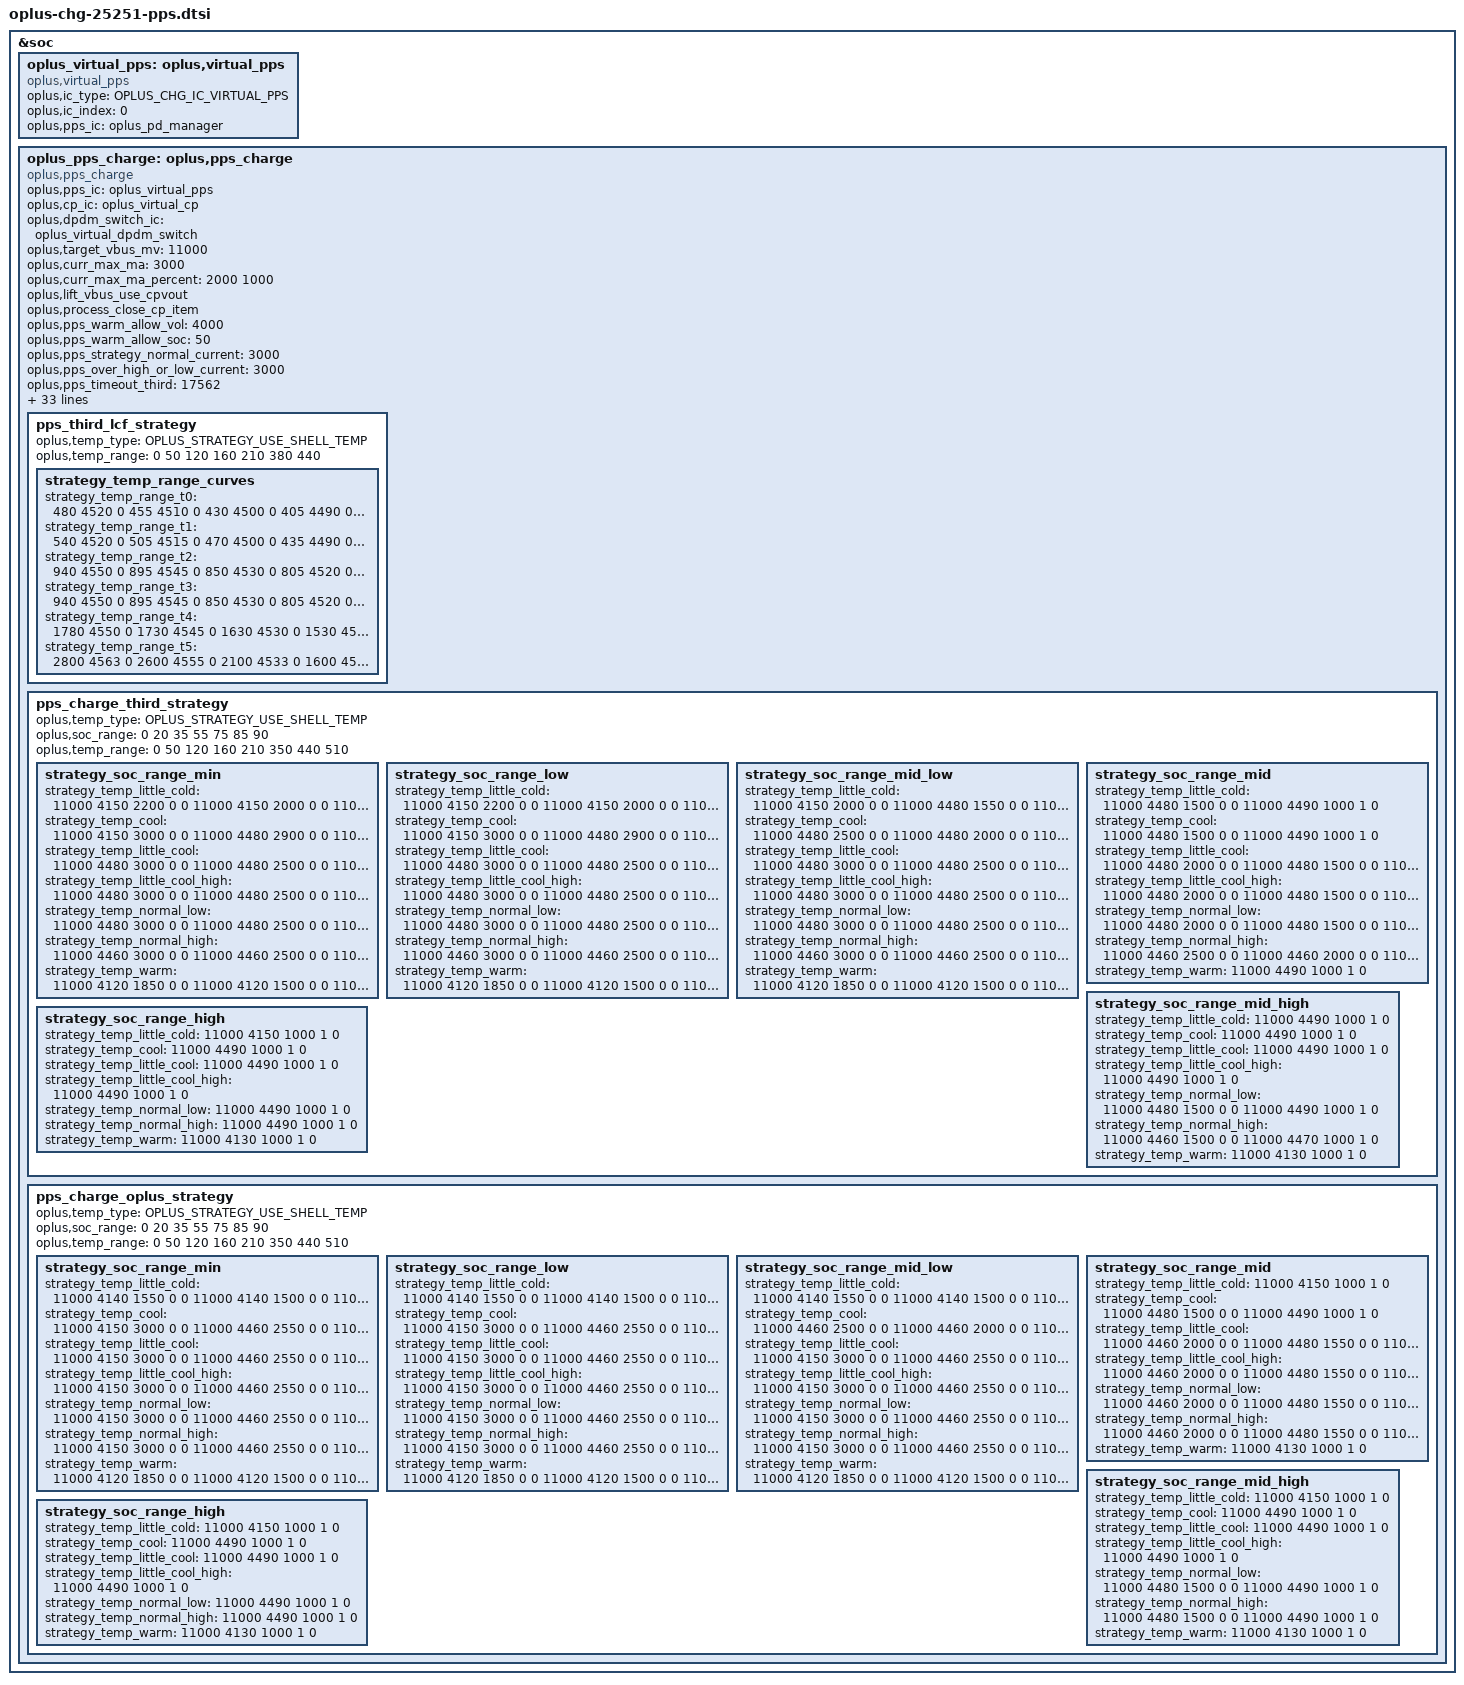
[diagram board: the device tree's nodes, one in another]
&soc {
	oplus_virtual_pps: oplus,virtual_pps {
		compatible = "oplus,virtual_pps";
		oplus,ic_type = <OPLUS_CHG_IC_VIRTUAL_PPS>;
		oplus,ic_index = <0>;
		oplus,pps_ic = <&oplus_pd_manager>;
	};
	oplus_pps_charge: oplus,pps_charge {
		compatible = "oplus,pps_charge";
		oplus,pps_ic = <&oplus_virtual_pps>;
		oplus,cp_ic = <&oplus_virtual_cp>;
		oplus,dpdm_switch_ic = <&oplus_virtual_dpdm_switch>;

		oplus,target_vbus_mv = <11000>;
		oplus,curr_max_ma = <3000>;
		oplus,curr_max_ma_percent = <2000 /* 75% ibus */
					     1000 /* 85% ibus */>;
		oplus,lift_vbus_use_cpvout;
		oplus,process_close_cp_item;

		oplus,pps_warm_allow_vol = <4000>;
		oplus,pps_warm_allow_soc = <50>;
		oplus,pps_strategy_normal_current = <3000>;
		oplus,pps_over_high_or_low_current = <3000>;
		oplus,pps_timeout_third = <17562>;
		oplus,pps_timeout_oplus = <17562>;
		oplus,pps_ibat_over_third = <7400>;
		oplus,pps_ibat_over_oplus = <7400>;
		oplus,pps_full_cool_sw_vbat = <4490>;
		oplus,pps_full_normal_sw_vbat = <4500>;
		oplus,pps_full_normal_hw_vbat = <4490>;
		oplus,pps_full_ffc_vbat = <4545>;
		oplus,pps_full_warm_vbat = <4130>;
		oplus,pps_full_cool_sw_vbat_third = <4490>;
		oplus,pps_full_normal_sw_vbat_third= <4490>;
		oplus,pps_full_normal_hw_vbat_third = <4500>;
		oplus,pps_current_change_timeout = <100>;
		oplus,pps_r_default = <270 45 10 45 20 20 20>;
		oplus,pps_rmos_mohm = <5>;
		oplus,pps_r_limit = <150 100 80 70 30>;
		oplus,pps_strategy_batt_high_temp = <395 420 440 390 415 435>;
		oplus,pps_strategy_high_current = <3000 2000 1300 3000 3000 2000>;
		oplus,pps_little_cool_high_temp = <210>;
		oplus,curve_strategy_name = "pps_ufcs_curve_v2";
		oplus,pps_charge_strategy_soc = <0 20 35 55 75 85 85>;
		oplus,pps_charge_strategy_temp = <0 50 120 160 350 440 510>;
		oplus,pps_low_curr_full_strategy_temp = <0 200 350 440>;

		oplus,plc_strategy-data = <&cp_2t1_simple_strategy>;
		oplus,plc_strategy-names = "default";

		oplus,temperature_strategy_name = "cgcl";
		oplus,temperature_strategy_data = <OPLUS_STRATEGY_USE_SHELL_TEMP
						    0   420 3000 1 0
						    415 440 2000 2 0
						    435 450 1300 2 1>;

		pps_third_lcf_strategy {
			oplus,temp_type = <OPLUS_STRATEGY_USE_SHELL_TEMP>;
			oplus,temp_range = <0 50 120 160 210 380 440>;

			strategy_temp_range_curves {
				strategy_temp_range_t0 =	<480 4520 0
								 455 4510 0
								 430 4500 0
								 405 4490 0
								 380 4480 1>;
				strategy_temp_range_t1 =	<540 4520 0
								 505 4515 0
								 470 4500 0
								 435 4490 0
								 400 4480 1>;
				strategy_temp_range_t2 =	<940 4550 0
								 895 4545 0
								 850 4530 0
								 805 4520 0
								 760 4510 1>;
				strategy_temp_range_t3 =	<940 4550 0
								 895 4545 0
								 850 4530 0
								 805 4520 0
								 760 4510 1>;
				strategy_temp_range_t4 =	<1780 4550 0
								 1730 4545 0
								 1630 4530 0
								 1530  4520 0
								 1380  4510 1>;
				strategy_temp_range_t5 =	<2800 4563 0
								 2600 4555 0
								 2100 4533 0
								 1600 4513 0
								 1000 4467 1>;
			};
		};

		pps_charge_third_strategy {
			oplus,temp_type = <OPLUS_STRATEGY_USE_SHELL_TEMP>;
			oplus,soc_range = <0 20 35 55 75 85 90>;
			oplus,temp_range = <0 50 120 160 210 350 440 510>;

			strategy_soc_range_min {
				strategy_temp_little_cold =	<11000 4150 2200 0 0
								11000 4150 2000 0 0
								11000 4480 1550 0 0
								11000 4480 1500 0 0
								11000 4490 1000 1 0>;
				strategy_temp_cool =		<11000 4150 3000 0 0
								11000 4480 2900 0 0
								11000 4480 2500 0 0
								11000 4480 2000 0 0
								11000 4480 1550 0 0
								11000 4480 1500 0 0
								11000 4490 1000 1 0>;
				strategy_temp_little_cool =	<11000 4480 3000 0 0
								11000 4480 2500 0 0
								11000 4480 2000 0 0
								11000 4480 1500 0 0
								11000 4490 1000 1 0>;
				strategy_temp_little_cool_high = <11000 4480 3000 0 0
								11000 4480 2500 0 0
								11000 4480 2000 0 0
								11000 4480 1500 0 0
								11000 4490 1000 1 0>;
				strategy_temp_normal_low =	<11000 4480 3000 0 0
								11000 4480 2500 0 0
								11000 4480 2000 0 0
								11000 4480 1500 0 0
								11000 4490 1000 1 0>;
				strategy_temp_normal_high =	<11000 4460 3000 0 0
								11000 4460 2500 0 0
								11000 4460 2000 0 0
								11000 4460 1500 0 0
								11000 4470 1000 1 0>;
				strategy_temp_warm =		<11000 4120 1850 0 0
								11000 4120 1500 0 0
								11000 4130 1000 1 0>;
			};
			strategy_soc_range_low {
				strategy_temp_little_cold =	<11000 4150 2200 0 0
								11000 4150 2000 0 0
								11000 4480 1550 0 0
								11000 4480 1500 0 0
								11000 4490 1000 1 0>;
				strategy_temp_cool =		<11000 4150 3000 0 0
								11000 4480 2900 0 0
								11000 4480 2500 0 0
								11000 4480 2000 0 0
								11000 4480 1550 0 0
								11000 4480 1500 0 0
								11000 4490 1000 1 0>;
				strategy_temp_little_cool =	<11000 4480 3000 0 0
								11000 4480 2500 0 0
								11000 4480 2000 0 0
								11000 4480 1500 0 0
								11000 4490 1000 1 0>;
				strategy_temp_little_cool_high = <11000 4480 3000 0 0
								11000 4480 2500 0 0
								11000 4480 2000 0 0
								11000 4480 1500 0 0
								11000 4490 1000 1 0>;
				strategy_temp_normal_low =	<11000 4480 3000 0 0
								11000 4480 2500 0 0
								11000 4480 2000 0 0
								11000 4480 1500 0 0
								11000 4490 1000 1 0>;
				strategy_temp_normal_high =	<11000 4460 3000 0 0
								11000 4460 2500 0 0
								11000 4460 2000 0 0
								11000 4460 1500 0 0
								11000 4470 1000 1 0>;
				strategy_temp_warm =		<11000 4120 1850 0 0
								11000 4120 1500 0 0
								11000 4130 1000 1 0>;
			};
			strategy_soc_range_mid_low {
				strategy_temp_little_cold =	<11000 4150 2000 0 0
								11000 4480 1550 0 0
								11000 4480 1500 0 0
								11000 4490 1000 1 0>;
				strategy_temp_cool =		<11000 4480 2500 0 0
								11000 4480 2000 0 0
								11000 4480 1550 0 0
								11000 4480 1500 0 0
								11000 4490 1000 1 0>;
				strategy_temp_little_cool =	<11000 4480 3000 0 0
								11000 4480 2500 0 0
								11000 4480 2000 0 0
								11000 4480 1500 0 0
								11000 4490 1000 1 0>;
				strategy_temp_little_cool_high = <11000 4480 3000 0 0
								11000 4480 2500 0 0
								11000 4480 2000 0 0
								11000 4480 1500 0 0
								11000 4490 1000 1 0>;
				strategy_temp_normal_low =	<11000 4480 3000 0 0
								11000 4480 2500 0 0
								11000 4480 2000 0 0
								11000 4480 1500 0 0
								11000 4490 1000 1 0>;
				strategy_temp_normal_high =	<11000 4460 3000 0 0
								11000 4460 2500 0 0
								11000 4460 2000 0 0
								11000 4460 1500 0 0
								11000 4470 1000 1 0>;
				strategy_temp_warm =		<11000 4120 1850 0 0
								11000 4120 1500 0 0
								11000 4130 1000 1 0>;

			};
			strategy_soc_range_mid {
				strategy_temp_little_cold =	<11000 4480 1500 0 0
								11000 4490 1000 1 0>;
				strategy_temp_cool =		<11000 4480 1500 0 0
								11000 4490 1000 1 0>;
				strategy_temp_little_cool =	<11000 4480 2000 0 0
								11000 4480 1500 0 0
								11000 4490 1000 1 0>;
				strategy_temp_little_cool_high = <11000 4480 2000 0 0
								11000 4480 1500 0 0
								11000 4490 1000 1 0>;
				strategy_temp_normal_low =	<11000 4480 2000 0 0
								11000 4480 1500 0 0
								11000 4490 1000 1 0>;
				strategy_temp_normal_high =	<11000 4460 2500 0 0
								11000 4460 2000 0 0
								11000 4460 1500 0 0
								11000 4470 1000 1 0>;
				strategy_temp_warm =		<11000 4490 1000 1 0>;
			};
			strategy_soc_range_mid_high {
				strategy_temp_little_cold =	<11000 4490 1000 1 0>;
				strategy_temp_cool =		<11000 4490 1000 1 0>;
				strategy_temp_little_cool =	<11000 4490 1000 1 0>;
				strategy_temp_little_cool_high = <11000 4490 1000 1 0>;
				strategy_temp_normal_low =	<11000 4480 1500 0 0
								11000 4490 1000 1 0>;
				strategy_temp_normal_high =	<11000 4460 1500 0 0
								11000 4470 1000 1 0>;
				strategy_temp_warm =		<11000 4130 1000 1 0>;
			};
			strategy_soc_range_high {
				strategy_temp_little_cold =	<11000 4150 1000 1 0>;
				strategy_temp_cool =		<11000 4490 1000 1 0>;
				strategy_temp_little_cool =	<11000 4490 1000 1 0>;
				strategy_temp_little_cool_high = <11000 4490 1000 1 0>;
				strategy_temp_normal_low =	<11000 4490 1000 1 0>;
				strategy_temp_normal_high =	<11000 4490 1000 1 0>;
				strategy_temp_warm =		<11000 4130 1000 1 0>;
			};
		};

		pps_charge_oplus_strategy {
			oplus,temp_type = <OPLUS_STRATEGY_USE_SHELL_TEMP>;
			oplus,soc_range = <0 20 35 55 75 85 90>;
			oplus,temp_range = <0 50 120 160 210 350 440 510>;

			strategy_soc_range_min {
				strategy_temp_little_cold =	<11000 4140 1550 0 0
								11000 4140 1500 0 0
								11000 4150 1000 1 0>;
				strategy_temp_cool =		<11000 4150 3000 0 0
								11000 4460 2550 0 0
								11000 4460 2500 0 0
								11000 4460 2000 0 0
								11000 4480 1550 0 0
								11000 4480 1500 0 0
								11000 4490 1000 1 0>;
				strategy_temp_little_cool =	<11000 4150 3000 0 0
								11000 4460 2550 0 0
								11000 4460 2500 0 0
								11000 4460 2000 0 0
								11000 4480 1550 0 0
								11000 4480 1500 0 0
								11000 4490 1000 1 0>;
				strategy_temp_little_cool_high = <11000 4150 3000 0 0
								11000 4460 2550 0 0
								11000 4460 2500 0 0
								11000 4460 2000 0 0
								11000 4480 1550 0 0
								11000 4480 1500 0 0
								11000 4490 1000 1 0>;
				strategy_temp_normal_low =	<11000 4150 3000 0 0
								11000 4460 2550 0 0
								11000 4460 2500 0 0
								11000 4460 2000 0 0
								11000 4480 1550 0 0
								11000 4480 1500 0 0
								11000 4490 1000 1 0>;
				strategy_temp_normal_high =	<11000 4150 3000 0 0
								11000 4460 2550 0 0
								11000 4460 2500 0 0
								11000 4460 2000 0 0
								11000 4480 1550 0 0
								11000 4480 1500 0 0
								11000 4490 1000 1 0>;
				strategy_temp_warm =		<11000 4120 1850 0 0
								11000 4120 1500 0 0
								11000 4130 1000 1 0>;
			};
			strategy_soc_range_low {
				strategy_temp_little_cold =	<11000 4140 1550 0 0
								11000 4140 1500 0 0
								11000 4150 1000 1 0>;
				strategy_temp_cool =		<11000 4150 3000 0 0
								11000 4460 2550 0 0
								11000 4460 2500 0 0
								11000 4460 2000 0 0
								11000 4480 1550 0 0
								11000 4480 1500 0 0
								11000 4490 1000 1 0>;
				strategy_temp_little_cool =	<11000 4150 3000 0 0
								11000 4460 2550 0 0
								11000 4460 2500 0 0
								11000 4460 2000 0 0
								11000 4480 1550 0 0
								11000 4480 1500 0 0
								11000 4490 1000 1 0>;
				strategy_temp_little_cool_high = <11000 4150 3000 0 0
								11000 4460 2550 0 0
								11000 4460 2500 0 0
								11000 4460 2000 0 0
								11000 4480 1550 0 0
								11000 4480 1500 0 0
								11000 4490 1000 1 0>;
				strategy_temp_normal_low =	<11000 4150 3000 0 0
								11000 4460 2550 0 0
								11000 4460 2500 0 0
								11000 4460 2000 0 0
								11000 4480 1550 0 0
								11000 4480 1500 0 0
								11000 4490 1000 1 0>;
				strategy_temp_normal_high =	<11000 4150 3000 0 0
								11000 4460 2550 0 0
								11000 4460 2500 0 0
								11000 4460 2000 0 0
								11000 4480 1550 0 0
								11000 4480 1500 0 0
								11000 4490 1000 1 0>;
				strategy_temp_warm =		<11000 4120 1850 0 0
								11000 4120 1500 0 0
								11000 4130 1000 1 0>;
			};
			strategy_soc_range_mid_low {
				strategy_temp_little_cold =	<11000 4140 1550 0 0
								11000 4140 1500 0 0
								11000 4150 1000 1 0>;
				strategy_temp_cool =		<11000 4460 2500 0 0
								11000 4460 2000 0 0
								11000 4480 1550 0 0
								11000 4480 1500 0 0
								11000 4490 1000 1 0>;
				strategy_temp_little_cool =	<11000 4150 3000 0 0
								11000 4460 2550 0 0
								11000 4460 2500 0 0
								11000 4460 2000 0 0
								11000 4480 1550 0 0
								11000 4480 1500 0 0
								11000 4490 1000 1 0>;
				strategy_temp_little_cool_high = <11000 4150 3000 0 0
								11000 4460 2550 0 0
								11000 4460 2500 0 0
								11000 4460 2000 0 0
								11000 4480 1550 0 0
								11000 4480 1500 0 0
								11000 4490 1000 1 0>;
				strategy_temp_normal_low =	<11000 4150 3000 0 0
								11000 4460 2550 0 0
								11000 4460 2500 0 0
								11000 4460 2000 0 0
								11000 4480 1550 0 0
								11000 4480 1500 0 0
								11000 4490 1000 1 0>;
				strategy_temp_normal_high =	<11000 4150 3000 0 0
								11000 4460 2550 0 0
								11000 4460 2500 0 0
								11000 4460 2000 0 0
								11000 4480 1550 0 0
								11000 4480 1500 0 0
								11000 4490 1000 1 0>;
				strategy_temp_warm =		<11000 4120 1850 0 0
								11000 4120 1500 0 0
								11000 4130 1000 1 0>;

			};
			strategy_soc_range_mid {
				strategy_temp_little_cold =	<11000 4150 1000 1 0>;
				strategy_temp_cool =		<11000 4480 1500 0 0
								11000 4490 1000 1 0>;
				strategy_temp_little_cool =	<11000 4460 2000 0 0
								11000 4480 1550 0 0
								11000 4480 1500 0 0
								11000 4490 1000 1 0>;
				strategy_temp_little_cool_high = <11000 4460 2000 0 0
								11000 4480 1550 0 0
								11000 4480 1500 0 0
								11000 4490 1000 1 0>;
				strategy_temp_normal_low =	<11000 4460 2000 0 0
								11000 4480 1550 0 0
								11000 4480 1500 0 0
								11000 4490 1000 1 0>;
				strategy_temp_normal_high =	<11000 4460 2000 0 0
								11000 4480 1550 0 0
								11000 4480 1500 0 0
								11000 4490 1000 1 0>;
				strategy_temp_warm =		<11000 4130 1000 1 0>;
			};
			strategy_soc_range_mid_high {
				strategy_temp_little_cold =	<11000 4150 1000 1 0>;
				strategy_temp_cool =		<11000 4490 1000 1 0>;
				strategy_temp_little_cool =	<11000 4490 1000 1 0>;
				strategy_temp_little_cool_high = <11000 4490 1000 1 0>;
				strategy_temp_normal_low =	<11000 4480 1500 0 0
								11000 4490 1000 1 0>;
				strategy_temp_normal_high =	<11000 4480 1500 0 0
								11000 4490 1000 1 0>;
				strategy_temp_warm =		<11000 4130 1000 1 0>;
			};
			strategy_soc_range_high {
				strategy_temp_little_cold =	<11000 4150 1000 1 0>;
				strategy_temp_cool =		<11000 4490 1000 1 0>;
				strategy_temp_little_cool =	<11000 4490 1000 1 0>;
				strategy_temp_little_cool_high = <11000 4490 1000 1 0>;
				strategy_temp_normal_low =	<11000 4490 1000 1 0>;
				strategy_temp_normal_high =	<11000 4490 1000 1 0>;
				strategy_temp_warm =		<11000 4130 1000 1 0>;
			};
		};
	};
};
